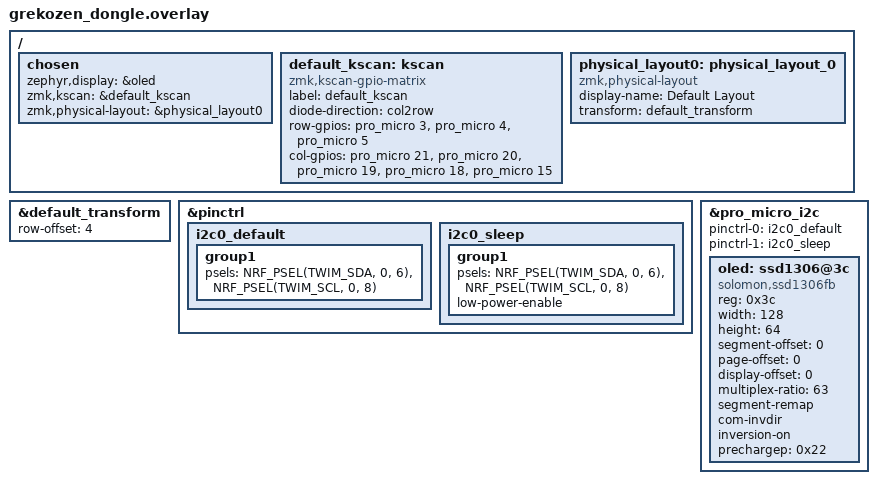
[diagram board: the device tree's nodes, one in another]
#include <dt-bindings/zmk/matrix_transform.h>
#include "grekozen.dtsi"

&default_transform {
  row-offset = <4>;
};

/ {
    chosen {
        zephyr,display = &oled; 
        zmk,kscan = &default_kscan;
        zmk,physical-layout = &physical_layout0;
    };

    default_kscan: kscan {
        compatible = "zmk,kscan-gpio-matrix";
        label = "default_kscan";
        diode-direction = "col2row";

        row-gpios = <&pro_micro 3 (GPIO_ACTIVE_HIGH | GPIO_PULL_DOWN)>,
                    <&pro_micro 4 (GPIO_ACTIVE_HIGH | GPIO_PULL_DOWN)>,
                    <&pro_micro 5 (GPIO_ACTIVE_HIGH | GPIO_PULL_DOWN)>;
        
        col-gpios = <&pro_micro 21 GPIO_ACTIVE_HIGH>,
                    <&pro_micro 20 GPIO_ACTIVE_HIGH>,
                    <&pro_micro 19 GPIO_ACTIVE_HIGH>,
                    <&pro_micro 18 GPIO_ACTIVE_HIGH>,
                    <&pro_micro 15 GPIO_ACTIVE_HIGH>;
    };

    physical_layout0: physical_layout_0 {
        compatible = "zmk,physical-layout";
        display-name = "Default Layout";
        transform = <&default_transform>;
    };
};

&pinctrl {
    i2c0_default: i2c0_default {
        group1 {
            psels = <NRF_PSEL(TWIM_SDA, 0, 6)>,
                    <NRF_PSEL(TWIM_SCL, 0, 8)>;
        };
    };

    i2c0_sleep: i2c0_sleep {
        group1 {
            psels = <NRF_PSEL(TWIM_SDA, 0, 6)>,
                    <NRF_PSEL(TWIM_SCL, 0, 8)>;
            low-power-enable;
        };
    };
};

&pro_micro_i2c {
    status = "okay";
    pinctrl-0 = <&i2c0_default>;
    pinctrl-1 = <&i2c0_sleep>;
    pinctrl-names = "default", "sleep";

    oled: ssd1306@3c {
        compatible = "solomon,ssd1306fb";
        reg = <0x3c>;
        width = <128>;
        height = <64>;
        segment-offset = <0>;
        page-offset = <0>;
        display-offset = <0>;
        multiplex-ratio = <63>;
        segment-remap;
        com-invdir;
        inversion-on;
        prechargep = <0x22>;
    };
};
